# CIU32L051 register map
File version: 1.0.0
Registers are 32-bit, read-write, reset 0x0 unless marked. A register's access mark holds for its fields unless they carry their own. Offsets are from the block's base; lines under a group give offsets from that group; [hi:lo] are bit positions; {n}, {i} and the like mark numbered series; 'fields as' and 'values as' point back to an identical list; <NAME> marks a mode.

## Memory map
0x40000400 TIM3 size 0x400
0x40000800 TIM4 size 0x400
0x40000C00 TIM5 size 0x400
0x40001000 TIM8 size 0x400
0x40002400 LCD size 0x400
0x40002800 RTC size 0x400
0x40002C00 WWDG size 0x400
0x40003000 IWDG size 0x400
0x40003800 SPI2 size 0x400
0x40004400 UART2 size 0x400
0x40004800 UART3 size 0x400
0x40004C00 UART4 size 0x400
0x40005400 I2C1 size 0x400
0x40007000 PMU size 0x400
0x40007C00 LPTIM1 size 0x400
0x40008000 LPUART1 size 0x400
0x40008400 LPUART2 size 0x400
0x40009000 LPTIM2 size 0x400
0x4000B000 TAMP size 0x400
0x40010000 SYSCFG size 0x400
0x400101B0 VREFBUF size 0x400
0x40010200 COMP size 0x400
0x40012400 ADC size 0x400
0x40013000 SPI1 size 0x400
0x40013800 USART1 size 0x400
0x40015800 DBG size 0x400
0x40018000 TRNG size 0x400
0x40020000 DMA size 0x400
0x40021000 RCC size 0x400
0x40021800 EXTI size 0x400
0x40022000 FLASH size 0x400
0x40023000 CRC size 0x400
0x40026000 AES size 0x400
0x50000000 GPIOA size 0x400
0x50000400 GPIOB size 0x400
0x50000800 GPIOC size 0x400
0x50000C00 GPIOD size 0x400
0x50001400 GPIOF size 0x400
0xE0000000 SCB size 0x400
0xE000E010 SYSTICK size 0x400
0xE000E100 NVIC size 0x400

## Interrupts
0 WWDG
1 PVD (PMU)
2 RTC_TAMP (RTC)
3 FLASH
4 RCC
5 EXTI_1_0 (EXTI)
6 EXTI_3_2 (EXTI)
7 EXTI_15_4 (EXTI)
8 LCD
9 DMA_Channel0 (DMA)
10 DMA_Channel1 (DMA)
12 ADC_COMP (ADC)
15 TIM3
16 TIM4
17 TIM5
18 TIM8
19 AES
20 LPTIM1
21 I2C1
23 SPI1
24 SPI2
25 USART1
26 UART2
27 UART3_UART4 (UART3)
28 LPUART1
29 TRNG
30 LPTIM2
31 LPUART2

## ADC
Base 0x40012400
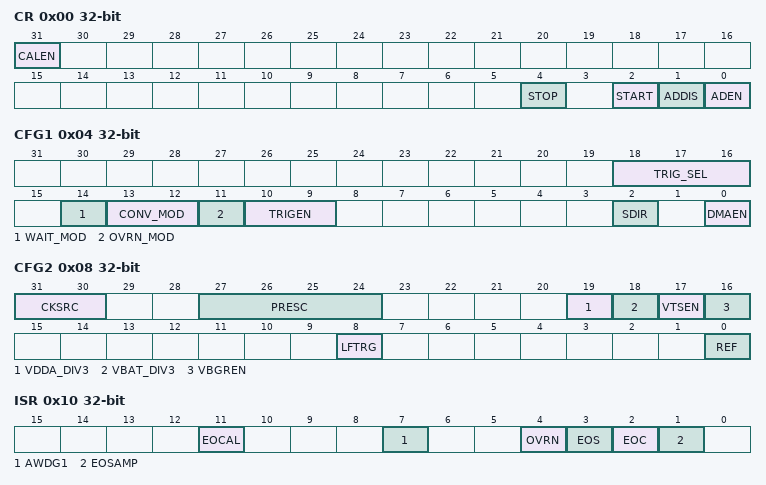
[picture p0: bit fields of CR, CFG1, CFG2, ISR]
0x00 CR
  [31] CALEN, [4] STOP, [2] START, [1] ADDIS, [0] ADEN
0x04 CFG1
  [18:16] TRIG_SEL, [14] WAIT_MOD, [13:12] CONV_MOD, [11] OVRN_MOD, [10:9] TRIGEN, [2] SDIR, [0] DMAEN
0x08 CFG2
  [31:30] CKSRC, [27:24] PRESC, [19] VDDA_DIV3, [18] VBAT_DIV3, [17] VTSEN, [16] VBGREN, [8] LFTRG, [0] REF
0x10 ISR
  [11] EOCAL, [7] AWDG1, [4] OVRN, [3] EOS, [2] EOC, [1] EOSAMP
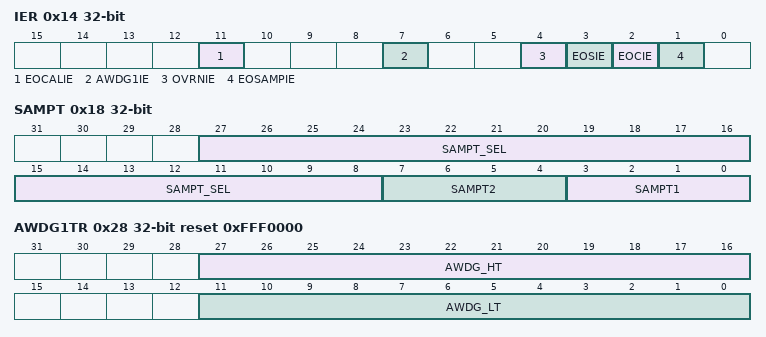
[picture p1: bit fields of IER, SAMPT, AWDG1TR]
0x14 IER
  [11] EOCALIE, [7] AWDG1IE, [4] OVRNIE, [3] EOSIE, [2] EOCIE, [1] EOSAMPIE
0x18 SAMPT
  [27:8] SAMPT_SEL, [7:4] SAMPT2, [3:0] SAMPT1
0x1C CHCFG
  [19:0] CHN
0x20 AWDG1CR
  [19:0] CHN
0x28 AWDG1TR reset 0xFFF0000
  [27:16] AWDG_HT, [11:0] AWDG_LT
0x30 CALFACT
  [5:0] CALFACT
0x40 DR
  [11:0] DATA

## AES
Base 0x40026000
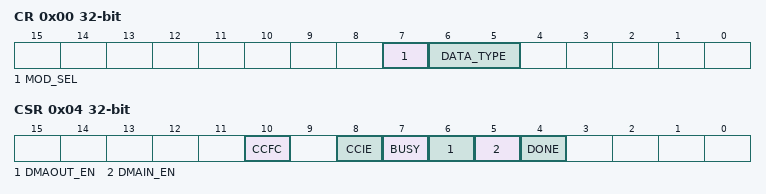
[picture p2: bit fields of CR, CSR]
0x00 CR
  [7] MOD_SEL, [6:5] DATA_TYPE
0x04 CSR
  [10] CCFC, [8] CCIE, [7] BUSY, [6] DMAOUT_EN, [5] DMAIN_EN, [4] DONE
{0x10+4i} KEYR{i} (i=0..3)
  [31:0] KEY
0x30 DR
  [31:0] DATA

## COMP
Base 0x40010200
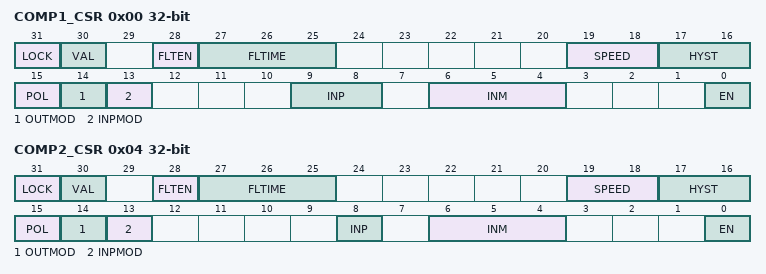
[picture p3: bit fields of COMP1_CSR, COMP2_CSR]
0x00 COMP1_CSR
  [31] LOCK, [30] VAL, [28] FLTEN, [27:25] FLTIME, [19:18] SPEED, [17:16] HYST, [15] POL, [14] OUTMOD, [13] INPMOD, [9:8] INP, [6:4] INM, [0] EN
0x04 COMP2_CSR
  [31] LOCK, [30] VAL, [28] FLTEN, [27:25] FLTIME, [19:18] SPEED, [17:16] HYST, [15] POL, [14] OUTMOD, [13] INPMOD, [8] INP, [6:4] INM, [0] EN

## CRC
Base 0x40023000
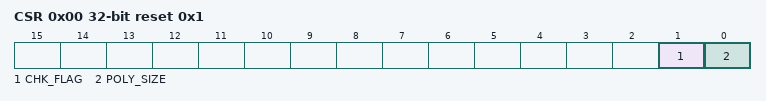
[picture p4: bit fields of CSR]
0x00 CSR reset 0x1
  [1] CHK_FLAG, [0] POLY_SIZE
0x04 RDR
  [31:0] RESULT
0x80 DR
  [7:0] DATA

## DBG
Base 0x40015800
0x00 CR
  [0] DBG_STOP
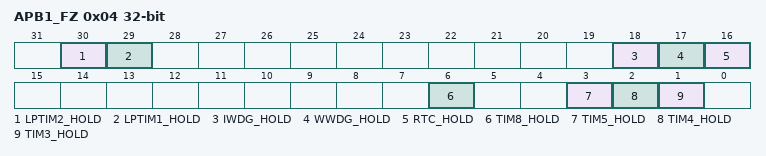
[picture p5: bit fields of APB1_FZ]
0x04 APB1_FZ
  [30] LPTIM2_HOLD, [29] LPTIM1_HOLD, [18] IWDG_HOLD, [17] WWDG_HOLD, [16] RTC_HOLD, [6] TIM8_HOLD, [3] TIM5_HOLD, [2] TIM4_HOLD, [1] TIM3_HOLD

## DMA
Base 0x40020000
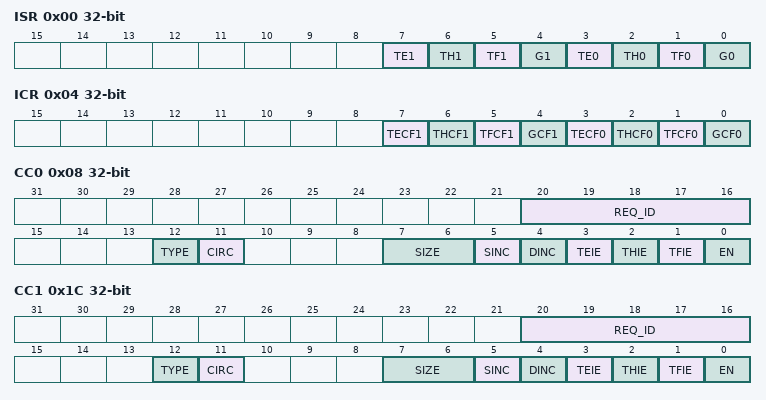
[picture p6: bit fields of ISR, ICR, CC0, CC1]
0x00 ISR
  [7] TE1, [6] TH1, [5] TF1, [4] G1, [3] TE0, [2] TH0, [1] TF0, [0] G0
0x04 ICR
  [7] TECF1, [6] THCF1, [5] TFCF1, [4] GCF1, [3] TECF0, [2] THCF0, [1] TFCF0, [0] GCF0
0x08 CC0
  [20:16] REQ_ID, [12] TYPE, [11] CIRC, [7:6] SIZE, [5] SINC, [4] DINC, [3] TEIE, [2] THIE, [1] TFIE, [0] EN
0x0C CNDTR0
  [15:0] NDT
0x10 CSAR0
  [31:0] SA
0x14 CDAR0
  [31:0] DA
0x1C CC1
  fields as CC0
0x20 CNDTR1
  [15:0] NDT
0x24 CSAR1
  [31:0] SA
0x28 CDAR1
  [31:0] DA
